# MIK32 register map
Vendor: Mikron JSC; Series: MIK32; File version: 1.0
Registers are 32-bit, read-write, reset 0x0 unless marked. A register's access mark holds for its fields unless they carry their own. Offsets are from the block's base; [hi:lo] are bit positions; {n}, {i} and the like mark numbered series; 'fields as' and 'values as' point back to an identical list.

## I2C_0 — Модуль обеспечивает интерфейс для связи контроллера и последовательной шины I2C
Base 0x00083800
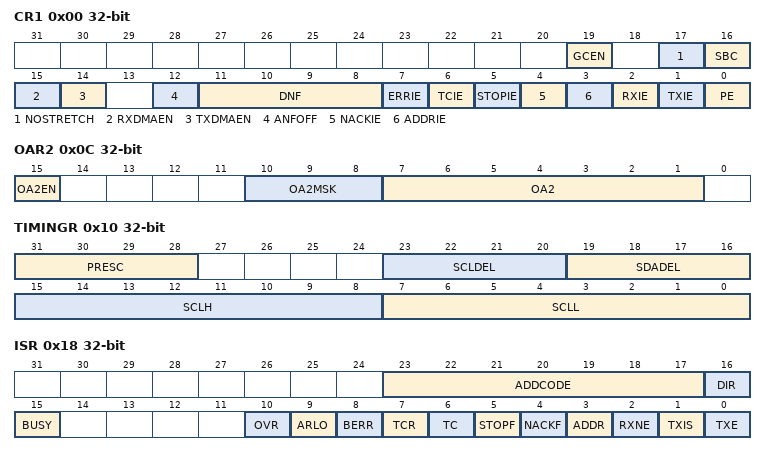
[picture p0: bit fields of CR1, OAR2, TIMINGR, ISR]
0x00 CR1 — Регистр управления 1
  [19] GCEN — Разрешение адреса общего вызова
    0=Disabled (Адрес 0b00000000 запрещен, формируется NACK); 1=Enable (Адрес 0b00000000 разрешен, формируется ACK)
  [17] NOSTRETCH — Отключение растягивания тактового сигнала в режиме «ведомый». Изменение значения допускается только при выключенном блоке (PE=0). В режиме «ведущий» бит должен быть установлен в «0»
    0=Stretching_enabled (Растягивание активно); 1=Stretching_disable (Растягивание выключено)
  [16] SBC — Режим аппаратного контроля передачи данных в режиме «ведомый»
    0=Disable (Контроль выключен); 1=Enable (Контроль включен)
  [15] RXDMAEN — Режим поддержки DMA при приёме данных
    0=Disable (Поддержка DMA выключена); 1=Enable (Поддержка DMA включенa)
  [14] TXDMAEN — Режим поддержки DMA при передаче данных
    0=Disable (Поддержка DMA выключена); 1=Enable (Поддержка DMA включена)
  [12] ANFOFF — Управление аналоговым фильтром шумов
    0=Disable (Фильтр выключен); 1=Enable (Фильтр включен)
  [11:8] DNF — Управление цифровым фильтром шумов. Изменение значения допускается только при выключенном блоке (PE=0)
    0=Disable (Цифровой фильтр выключен); 1=Цифровой фильтр установлен на 1 такт I2CCLK; 2=Цифровой фильтр установлен на 2 такта I2CCLK; 3=Цифровой фильтр установлен на 3 такта I2CCLK; 4=Цифровой фильтр установлен на 4 такта I2CCLK; {v}=Цифровой фильтр установлен на {v} тактов I2CCLK (v=5..13); 14=цифровой фильтр установлен на 14 тактов I2CCLK; 15=Цифровой фильтр установлен на 15 тактов I2CCLK
  [7] ERRIE — Разрешение прерывания при ошибке. События, вызывающие прерывание: - потеря арбитража (ARLO); - ошибка шины (BERR); - переполнение/недозагрузка (OVR).
    0=Disable (Прерывание запрещено); 1=Enable (Прерывание разрешено)
  [6] TCIE — Разрешение прерывания окончания передачи. События, вызывающие прерывание: - окончание передачи (TC); - окончание передачи при RELOAD=1 (TCR).
    values as ERRIE
  [5] STOPIE — Разрешение прерывания обнаружения STOP на линии
    values as ERRIE
  [4] NACKIE — Разрешение прерывания приём NACK
    values as ERRIE
  [3] ADDRIE — Разрешение прерывания соответствия адреса в режиме «ведомый»
    values as ERRIE
  [2] RXIE — Разрешение прерывания при приёме
    values as ERRIE
  [1] TXIE — Разрешение прерывания при передаче
    values as ERRIE
  [0] PE — Управление интерфейсом. После очистки, бит должен оставаться в «0» минимум три периода тактового сигнала APB
    0=Disable (Интерфейс выключен); 1=Enable (Интерфейс включен)
0x04 CR2 — Регистр управления 2
  [25] AUTOEND — Управление режимом автоматического окончания в режиме «ведущий». Бит устанавливается и очищается программой. Не имеет значения при установленном бите RELOAD и в режиме «ведомый»
    0=Disable (Режим автоматического окончания отключен); 1=Enable (Режим автоматического окончания включен)
  [24] RELOAD — Управление режимом перезаписи NBYTES. Бит устанавливается и очищается программой.
    0=Disable (Транзакция завершена после пересылки NBYTES байт данных (на шине ожидаются STOP или RESTART)); 1=Enable (Транзакция не завершена после пересылки NBYTES байт данных (значение NBYTES будет перезаписано))
  [23:16] NBYTES — Количество байт для приёма / передачи Не имеет значения в режиме «ведомый» при SBC=0 Не допускается изменение при установленном бите START
  [15] NACK — Формирование NACK в режиме «ведомый». Устанавливается программно, сбрасывается аппаратно: • после отправки NACK; • по событию STOP на шине; • при получении своего адреса ведомого; • PE=0.
    0=ASK (Отправка ACK после приёма текущего байта); 1=NACK (Отправка NACK после приёма текущего байта)
  [14] STOP — Формирование STOP в режиме «ведущий». Устанавливается программно, сбрасывается аппаратно по событию STOP на шине или при PE=0. Запись «0» в этот бит не имеет эффекта.
    0=STOP не формируется; 1=STOP (Формирование STOP после передачи текущего байта)
  [13] START — Формирование START. Устанавливается программно, сбрасывается аппаратно после отправки адреса, потере арбитража или PE=0. Запись «0» в этот бит не имеет эффекта. В режиме «ведущий» отправка первой части 10-битного адреса повторяется при получении NACK до получения ACK или до очистки бита START записью в бит ADDRCF
    0=START не формируется; 1=Start (формирование START после передачи текущего байта)
  [12] HEAD10R — Поддержка 10-битного адреса в режиме «ведущий», чтение Изменение этого бита при START=1 не допускается
    0=Complete (Ведущий отправляет полную последовательность для чтения для 10 битного адреса: Start + 2 байта адреса (запись) + ReStart + заголовок 10-битного адреса (чтение)); 1=Header (Ведущий отправляет только заголовок 10-битного адреса (чтение))
  [11] ADD10 — Режим 10-битного адреса (режим «ведущий»). Изменение этого бита при START=1 не допускается.
    0=7bit (Ведущий работает в режиме 7-битного адреса); 1=10bit (Ведущий работает в режиме 10-битного адреса)
  [10] RD_WRN — Направление передачи (режим «ведущий»). Изменение этого бита при START=1 не допускается.
    0=Write (Ведущий запрашивает транзакцию записи); 1=Read (Ведущий запрашивает транзакцию чтения)
  [7:1] SADD_7bit — Адрес ведомого (режим «ведущий») в режиме 7-битного адреса (ADD10 = 0). Изменение этих битов при START=1 не допускается.
  [9:0] SADD_10bit — Адрес ведомого (режим «ведущий») в режиме 10-битного адреса (ADD10 = 1). Изменение этих битов при START=1 не допускается.
0x08 OAR1 — Регистр адреса 1
  [15] OA1EN — Использование собственного адреса OA1
    0=NACK (При получении адреса OA1 формируется NACK); 1=ACK (При получении адреса OA1 формируется ACK)
  [10] OA1MODE — Режим 10-битного адреса OA1. Изменение бита допускается при OA1EN=0
    0=7bit (OA1 – 7-битный адрес); 1=10bit (OA1 – 10-битный адрес)
  [7:1] OA1_7bit — Собственный адрес 1 (7-битный режим). Изменение бита допускается при OA1EN=0.
  [9:0] OA1_10bit — Собственный адрес 1 (10-битный режим). Изменение бита допускается при OA1EN=0.
0x0C OAR2 — Регистр адреса 2
  [15] OA2EN — Использование собственного адреса OA2
    0=NACK (При получении адреса OA2 формируется NACK); 1=ACK (При получении адреса OA2 формируется ACK)
  [10:8] OA2MSK — Маска адреса OA2. Если OA2MSK ? 0, зарезервированные адреса I2C (0b0000xxx, 0b1111xxx) не подтверждаются, даже если адреса совпадают. Изменение битов допускается при OA2EN=0
    0=No_mask (Нет маски); {v}={v}_1_masked (Сравниваются только OA2[7:{v+1}]) (v=1..5); 6=6_1_masked (Сравниваются только OA2[7]); 7=7_1_masked (OA2[7:1] маскируются, подтверждаются (ACK) все 7-битные адреса (кроме зарезервированных))
  [7:1] OA2 — Собственный 7-битный адрес 2 Изменение битов допускается при OA2EN=0
0x10 TIMINGR — Регистр настройки временных ограничений. Регистр должен конфигурироваться, пока интерфейс заблокирован (PE=0).
  [31:28] PRESC — Предварительный делитель частоты I2CCLK. Используется для вычисления значения t_PRESC используемого счётчиками предустановки, удержания, низкого и высокого уровней. t_PRESC = (PRESC+1) x t_I2CCLK. Примечание: Регистр TIMING должен конфигурироваться, пока интерфейс заблокирован (PE=0).
  [23:20] SCLDEL — Длительность предустановки данных t_SU:DAT. Задержка между изменением SDA и фронтом SCL. t_SCLDEL = (SCLDEL+1) x t_PRESC Используется для генерации задержек t_SU:DAT. Примечание: Регистр TIMING должен конфигурироваться, пока интерфейс заблокирован (PE=0).
  [19:16] SDADEL — Длительность предустановки данных t_HD:DAT. Задержка между спадом SCL и изменением SDA в режиме ведущего и ведомого при NOSTRETCH = 0 t_SCADEL = (SCADEL+1) x t_PRESC Используется для генерации задержек t_HD:DAT. Примечание: Регистр TIMING должен конфигурироваться, пока интерфейс заблокирован (PE=0).
  [15:8] SCLH — Длительность удержания SCL в состоянии логической «1» в режиме «ведущий» t_SCLH = (SCLH+1) x t_PRESC Также используется для генерации задержек t_HD:STA и t_SU:STO. Примечание: Регистр TIMING должен конфигурироваться, пока интерфейс заблокирован (PE=0).
  [7:0] SCLL — Длительность удержания SCL в состоянии логического «0» в режиме «ведущий» t_SCLL = (SCLL+1) x t_PRESC Также используется для генерации задержек t_BUF и t_SU:STA. Примечание: Регистр TIMING должен конфигурироваться, пока интерфейс заблокирован (PE=0).
0x18 ISR — Регистр флагов прерываний
  [23:17] ADDCODE ro — Код совпавшего адреса. Обновляется в режиме «ведомый» при совпадении адреса (ADDR=1). В режиме 10-битного адреса содержит заголовок (5b11110) и два старших бита адреса.
  [16] DIR ro — Направление передачи (режим «ведомый»). Обновляется при совпадении адреса (ADDR=1)
    0=Write (Тип передачи «запись», ведомый переходит в режим приёмника); 1=Read (Тип передачи «чтение», ведомый переходит в режим передатчика)
  [15] BUSY ro — Флаг индикации занятой шины. Устанавливается после события START на шине и сбрасывается после события STOP на шине
  [10] OVR ro — Флаг переполнения/недозагрузки (режим «ведомый» при NOSTRETCH=1) Устанавливается аппаратно, сбрасывается программной установкой бита OVRCF или аппаратно при PE=0.
  [9] ARLO ro — Флаг проигрыша арбитража. Устанавливается аппаратно, сбрасывается программной установкой бита ARLOCF или аппаратно при PE=0.
  [8] BERR ro — Флаг ошибки шины Устанавливается аппаратно при детектировании неуместного события START или STOP на шине, если интерфейс участвует в передаче. Не устанавливается в фазе адреса в режиме «ведомый». Сбрасывается программной установкой бита BERRCF или аппаратно при PE=0.
  [7] TCR ro — Флаг окончания передачи (режим «ведущий» или «ведомый» с установленным битом SBC). Устанавливается аппаратно при RELOAD=1, после передачи NBYTES байт. Сбрасывается записью в NBYTES ненулевого значения или аппаратно при PE=0.
  [6] TC ro — Флаг окончания передачи (режим «ведущий»). Устанавливается аппаратно при RELOAD=0, AUTOEND=0, после передачи NBYTES байт. Сбрасывается программной установкой бита START или STOP или аппаратно при PE=0.
  [5] STOPF ro — Флаг детектирования STOP на шине. Устанавливается аппаратно, если интерфейс участвует в передаче. Сбрасывается программной установкой бита STOPCF или аппаратно при PE=0.
  [4] NACKF ro — Флаг «не получено подтверждение» (NACK). Устанавливается аппаратно, после передачи байта. Сбрасывается программной установкой бита NACKCF или аппаратно при PE=0.
  [3] ADDR ro — Флаг соответствия адреса (режим «ведомый»). Устанавливается аппаратно, если полученный адрес совпадает с одним из разрешенных в OAR1, OAR2. Сбрасывается программной установкой бита ADDRCF или аппаратно при PE=0.
  [2] RXNE — Флаг «буфер принятых данных заполнен» (режимы приёма). Устанавливается аппаратно, после записи принятых данных в регистр RXDR. Сбрасывается при чтении RXDR или аппаратно при PE=0.
  [1] TXIS ro — Состояние прерывания передатчика. Устанавливается аппаратно, когда регистр TXDR пуст и следующий байт данных должен быть в него записан. Сбрасывается записью следующего байта данных в регистр TXDR или аппаратно при PE=0. Этот бит может быть установлен программой только при NOSTRETCH=1 для выработки события TXIS (в результате: прерывание, при TXIE=1 или DMA запрос, при TXDMAEN=1)
  [0] TXE ro — Флаг «буфер передаваемых данных» TXDR пуст (режимы отправки). Устанавливается аппаратно, если буфер пуст; при PE=0 или программно, чтобы сбросить содержимое регистра TXDR. Сбрасывается записью следующего байта данных в регистр TXDR.
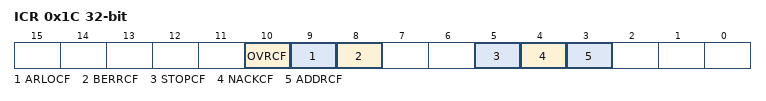
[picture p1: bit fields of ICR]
0x1C ICR wo — Регистр сроса флагов прерываний
  [10] OVRCF — Сброс флага прерывания переполнения/недозагрузки
  [9] ARLOCF — Сброс флага проигрыша арбитража
  [8] BERRCF — Сброс флага ошибки шины
  [5] STOPCF — Сброс флага детектирования STOP на шине
  [4] NACKCF — Сброс флага «не получено подтверждение» (NACK)
  [3] ADDRCF — Сброс флага соответствия адреса
0x24 RXDR ro — Регистр принятых данных
  [7:0] TXDATA — Буфер принятых данных
0x28 TXDR — Регистр передаваемых данных
  [7:0] TXDATA — Буфер передаваемых данных

## I2C_1 — Модуль обеспечивает интерфейс для связи контроллера и последовательной шины I2C
Base 0x00083C00
Registers as I2C_0; these are added or differ:
0x04 CR2 — Регистр управления 2
  [25] AUTOEND — Управление режимом автоматического окончания в режиме «ведущий». Бит устанавливается и очищается программой. Не имеет значения при установленном бите RELOAD и в режиме «ведомый»
    0=Disable (Режим автоматического окончания отключен); 1=Enable (Режим автоматического окончания включен)
  [24] RELOAD — Управление режимом перезаписи NBYTES. Бит устанавливается и очищается программой.
    values as I2C_0.CR2.RELOAD
  [23:16] NBYTES — Количество байт для приёма / передачи Не имеет значения в режиме «ведомый» при SBC=0. Не допускается изменение при установленном бите START
  [15] NACK — Формирование NACK в режиме «ведомый». Устанавливается программно, сбрасывается аппаратно: • после отправки NACK; • по событию STOP на шине; • при получении своего адреса ведомого; • PE=0.
    0=ASK (Отправка ACK после приёма текущего байта); 1=NACK (Отправка NACK после приёма текущего байта)
  [14] STOP — Формирование STOP в режиме «ведущий». Устанавливается программно, сбрасывается аппаратно по событию STOP на шине или при PE=0. Запись «0» в этот бит не имеет эффекта.
    0=STOP не формируется; 1=STOP (Формирование STOP после передачи текущего байта)
  [13] START — Формирование START. Устанавливается программно, сбрасывается аппаратно после отправки адреса, потере арбитража или PE=0. Запись «0» в этот бит не имеет эффекта. В режиме «ведущий» отправка первой части 10-битного адреса повторяется при получении NACK до получения ACK или до очистки бита START записью в бит ADDRCF
    0=START не формируется; 1=Start (формирование START после передачи текущего байта)
  [12] HEAD10R — Поддержка 10-битного адреса в режиме «ведущий», чтение. Изменение этого бита при START=1 не допускается
    values as I2C_0.CR2.HEAD10R
  [11] ADD10 — Режим 10-битного адреса (режим «ведущий»). Изменение этого бита при START=1 не допускается.
    0=7bit (Ведущий работает в режиме 7-битного адреса); 1=10bit (Ведущий работает в режиме 10-битного адреса)
  [10] RD_WRN — Направление передачи (режим «ведущий»). Изменение этого бита при START=1 не допускается.
    0=Write (Ведущий запрашивает транзакцию записи); 1=Read (Ведущий запрашивает транзакцию чтения)
  [7:1] SADD_7bit — Адрес ведомого (режим «ведущий») в режиме 7-битного адреса (ADD10 = 0). Изменение этих битов при START=1 не допускается.
  [9:0] SADD_10bit — Адрес ведомого (режим «ведущий») в режиме 10-битного адреса (ADD10 = 1). Изменение этих битов при START=1 не допускается.
